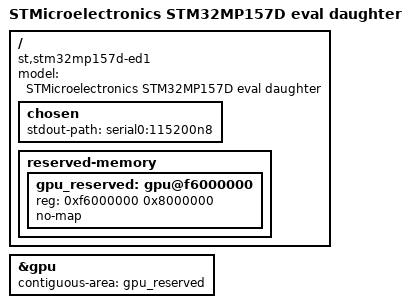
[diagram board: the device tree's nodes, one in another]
// SPDX-License-Identifier: (GPL-2.0+ OR BSD-3-Clause)
/*
 * Copyright (C) STMicroelectronics 2019 - All Rights Reserved
 * Author: Alexandre Torgue <alexandre.torgue@st.com> for STMicroelectronics.
 */
/dts-v1/;

#include "stm32mp157.dtsi"
#include "stm32mp15xd.dtsi"
#include "stm32mp15-pinctrl.dtsi"
#include "stm32mp15xxaa-pinctrl.dtsi"
#include "stm32mp15xx-edx.dtsi"

/ {
	model = "STMicroelectronics STM32MP157D eval daughter";
	compatible = "st,stm32mp157d-ed1", "st,stm32mp157";

	chosen {
		stdout-path = "serial0:115200n8";
	};

	reserved-memory {
		gpu_reserved: gpu@f6000000 {
			reg = <0xf6000000 0x8000000>;
			no-map;
		};
	};
};

&gpu {
	contiguous-area = <&gpu_reserved>;
};
